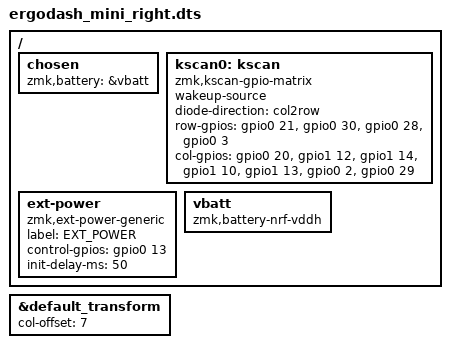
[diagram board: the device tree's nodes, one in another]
/*
*
* Copyright (c) 2021 Darryl deHaan
* SPDX-License-Identifier: MIT
*
*/
#include "ergodash_mini.dtsi"

;/{
    chosen {
        zmk,battery = &vbatt;
    };

    kscan0: kscan {
        compatible = "zmk,kscan-gpio-matrix";
        wakeup-source;
        diode-direction = "col2row";
        row-gpios
            = <&gpio0 21 (GPIO_ACTIVE_HIGH | GPIO_PULL_DOWN)>
            , <&gpio0 30 (GPIO_ACTIVE_HIGH | GPIO_PULL_DOWN)>
            , <&gpio0 28 (GPIO_ACTIVE_HIGH | GPIO_PULL_DOWN)>
            , <&gpio0 3 (GPIO_ACTIVE_HIGH | GPIO_PULL_DOWN)>
            ;

        col-gpios
           = <&gpio0 20 GPIO_ACTIVE_HIGH>  
            , <&gpio1 12 GPIO_ACTIVE_HIGH>
            , <&gpio1 14 GPIO_ACTIVE_HIGH>
            , <&gpio1 10 GPIO_ACTIVE_HIGH>
            , <&gpio1 13 GPIO_ACTIVE_HIGH>
            , <&gpio0 2 GPIO_ACTIVE_HIGH>
            , <&gpio0 29 GPIO_ACTIVE_HIGH>
            ;
    };

    ext-power {
        compatible = "zmk,ext-power-generic";
        label = "EXT_POWER";
        control-gpios = <&gpio0 13 GPIO_ACTIVE_HIGH>;
        init-delay-ms = <50>;
    };

     vbatt: vbatt {
        compatible = "zmk,battery-nrf-vddh";
    };

};
&default_transform {
    col-offset = <7>;
};
